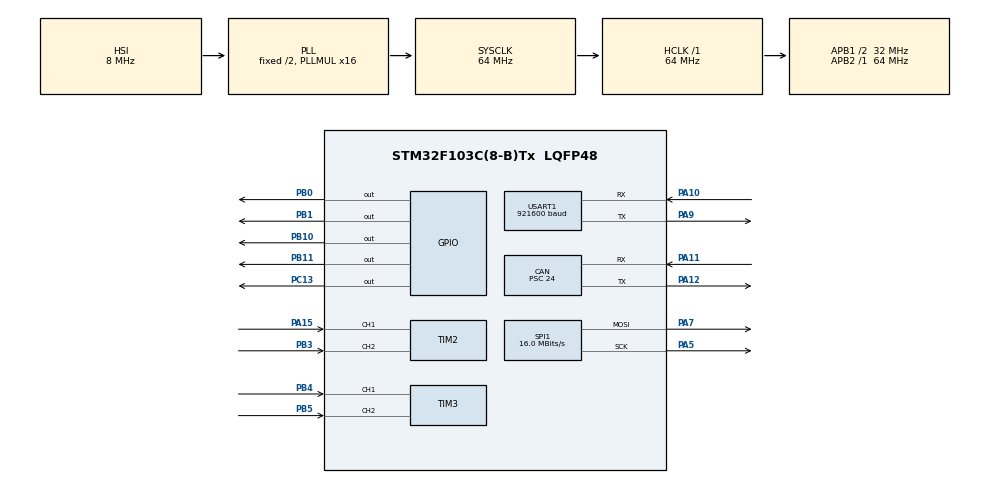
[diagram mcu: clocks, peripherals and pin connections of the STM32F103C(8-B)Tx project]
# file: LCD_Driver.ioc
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CAN.ABOM=ENABLE
CAN.AWUM=ENABLE
CAN.BS1=CAN_BS1_8TQ
CAN.BS2=CAN_BS2_6TQ
CAN.CalculateBaudRate=88888
CAN.CalculateTimeBit=11250
CAN.CalculateTimeQuantum=750.0
CAN.NART=ENABLE
CAN.Prescaler=24
CAN.SJW=CAN_SJW_1TQ
CAN.TXFP=DISABLE
Mcu.Family=STM32F1
Mcu.Name=STM32F103C(8-B)Tx
Mcu.Package=LQFP48
NVIC.CAN1_RX1_IRQn=true\:0\:0\:false\:false\:true\:true\:true\:true
NVIC.PriorityGroup=NVIC_PRIORITYGROUP_4
NVIC.USART1_IRQn=true\:0\:0\:false\:false\:true\:true\:true\:true
NVIC.USB_LP_CAN1_RX0_IRQn=true\:0\:0\:false\:false\:true\:true\:true\:true
PA10.Mode=Asynchronous
PA10.Signal=USART1_RX
PA11.Mode=CAN_Activate
PA11.Signal=CAN_RX
PA12.Mode=CAN_Activate
PA12.Signal=CAN_TX
PA13.Mode=Serial_Wire
PA13.Signal=SYS_JTMS-SWDIO
PA14.Mode=Serial_Wire
PA14.Signal=SYS_JTCK-SWCLK
PA15.Signal=S_TIM2_CH1_ETR
PA5.Mode=TX_Only_Simplex_Unidirect_Master
PA5.Signal=SPI1_SCK
PA7.Mode=TX_Only_Simplex_Unidirect_Master
PA7.Signal=SPI1_MOSI
PA9.Mode=Asynchronous
PA9.Signal=USART1_TX
PB0.Signal=GPIO_Output
PB1.Signal=GPIO_Output
PB10.Signal=GPIO_Output
PB11.Signal=GPIO_Output
PB3.Signal=S_TIM2_CH2
PB4.Signal=S_TIM3_CH1
PB5.Signal=S_TIM3_CH2
PC13-TAMPER-RTC.Signal=GPIO_Output
PD0-OSC_IN.Mode=HSE-External-Oscillator
PD0-OSC_IN.Signal=RCC_OSC_IN
PD1-OSC_OUT.Mode=HSE-External-Oscillator
PD1-OSC_OUT.Signal=RCC_OSC_OUT
ProjectManager.HeapSize=0x200
ProjectManager.StackSize=0x400
ProjectManager.TargetToolchain=MDK-ARM V5.32
RCC.AHBFreq_Value=64000000
RCC.APB1CLKDivider=RCC_HCLK_DIV2
RCC.APB1Freq_Value=32000000
RCC.APB1TimFreq_Value=64000000
RCC.APB2Freq_Value=64000000
RCC.APB2TimFreq_Value=64000000
RCC.HCLKFreq_Value=64000000
RCC.PLLMUL=RCC_PLL_MUL16
RCC.SYSCLKFreq_VALUE=64000000
RCC.SYSCLKSource=RCC_SYSCLKSOURCE_PLLCLK
RCC.USBFreq_Value=64000000
SH.S_TIM2_CH1_ETR.0=TIM2_CH1,Encoder_Interface
SH.S_TIM2_CH2.0=TIM2_CH2,Encoder_Interface
SH.S_TIM3_CH1.0=TIM3_CH1,Encoder_Interface
SH.S_TIM3_CH2.0=TIM3_CH2,Encoder_Interface
SPI1.BaudRatePrescaler=SPI_BAUDRATEPRESCALER_4
SPI1.CalculateBaudRate=16.0 MBits/s
SPI1.Direction=SPI_DIRECTION_2LINES
SPI1.Mode=SPI_MODE_MASTER
SPI1.VirtualType=VM_MASTER
USART1.BaudRate=921600
USART1.VirtualMode=VM_ASYNC
board=custom

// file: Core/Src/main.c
/* USER CODE BEGIN Header */
/**
  ******************************************************************************
  * @file           : main.c
  * @brief          : Main program body
  ******************************************************************************
  * @attention
  *
  * Copyright (c) 2026 STMicroelectronics.
  * All rights reserved.
  *
  * This software is licensed under terms that can be found in the LICENSE file
  * in the root directory of this software component.
  * If no LICENSE file comes with this software, it is provided AS-IS.
  *
  ******************************************************************************
  */
/* USER CODE END Header */
#include "main.h"
#include "can.h"
#include "spi.h"
#include "tim.h"
#include "usart.h"
#include "gpio.h"

/* USER CODE BEGIN Includes */

#include "main.h"
#include "ST7735.h"

#include "test.h"

/* USER CODE END Includes */

void SystemClock_Config(void);

int main(void)
{

  /* MCU Configuration--------------------------------------------------------*/

  /* Reset of all peripherals, Initializes the Flash interface and the Systick. */
  HAL_Init();

  /* Configure the system clock */
  SystemClock_Config();

  /* Initialize all configured peripherals */
  MX_GPIO_Init();
  MX_SPI1_Init();
  MX_USART1_UART_Init();
  MX_TIM2_Init();
  MX_TIM3_Init();
  MX_CAN_Init();
  /* USER CODE BEGIN 2 */

	LCD_Init();
	LCD_Fill(0,0,128,160 ,YELLOW);

Test_Display();

  /* USER CODE END 2 */

  /* Infinite loop */
  while (1)
  {

    /* USER CODE BEGIN 3 */

/*tset
// 测试写入16位数据 0x1234

//	  LCD_Write16(0x1234);
// 期望：先发送 0x12，再发送 0x34
// 原代码：先发送 0x12，然后发送 0x34（但写法容易引起误解）
// 修正后：先发送 0x12，再发送 0x34（写法清晰，类型明确）

uint8_t aaa[100] = {
    1, 2, 3, 4, 5, 6, 7, 8, 9, 10,
    11, 12, 13, 14, 15, 16, 17, 18, 19, 20,
    21, 22, 23, 24, 25, 26, 27, 28, 29, 30,
    31, 32, 33, 34, 35, 36, 37, 38, 39, 40,
    41, 42, 43, 44, 45, 46, 47, 48, 49, 50,
    51, 52, 53, 54, 55, 56, 57, 58, 59, 60,
    61, 62, 63, 64, 65, 66, 67, 68, 69, 70,
    71, 72, 73, 74, 75, 76, 77, 78, 79, 80,
    81, 82, 83, 84, 85, 86, 87, 88, 89, 90,
    91, 92, 93, 94, 95, 96, 97, 98, 99, 100
};
	  LCD_Txn(aaa,100);

	  HAL_Delay(900);
*///test

  }

  /* USER CODE END 3 */
}

void SystemClock_Config(void)
{
  RCC_OscInitTypeDef RCC_OscInitStruct = {0};
  RCC_ClkInitTypeDef RCC_ClkInitStruct = {0};

  /** Initializes the RCC Oscillators according to the specified parameters
  * in the RCC_OscInitTypeDef structure.
  */
  RCC_OscInitStruct.OscillatorType = RCC_OSCILLATORTYPE_HSI;
  RCC_OscInitStruct.HSIState = RCC_HSI_ON;
  RCC_OscInitStruct.HSICalibrationValue = RCC_HSICALIBRATION_DEFAULT;
  RCC_OscInitStruct.PLL.PLLState = RCC_PLL_ON;
  RCC_OscInitStruct.PLL.PLLSource = RCC_PLLSOURCE_HSI_DIV2;
  RCC_OscInitStruct.PLL.PLLMUL = RCC_PLL_MUL16;
  if (HAL_RCC_OscConfig(&RCC_OscInitStruct) != HAL_OK)
  {
    Error_Handler();
  }

  /** Initializes the CPU, AHB and APB buses clocks
  */
  RCC_ClkInitStruct.ClockType = RCC_CLOCKTYPE_HCLK|RCC_CLOCKTYPE_SYSCLK
                              |RCC_CLOCKTYPE_PCLK1|RCC_CLOCKTYPE_PCLK2;
  RCC_ClkInitStruct.SYSCLKSource = RCC_SYSCLKSOURCE_PLLCLK;
  RCC_ClkInitStruct.AHBCLKDivider = RCC_SYSCLK_DIV1;
  RCC_ClkInitStruct.APB1CLKDivider = RCC_HCLK_DIV2;
  RCC_ClkInitStruct.APB2CLKDivider = RCC_HCLK_DIV1;

  if (HAL_RCC_ClockConfig(&RCC_ClkInitStruct, FLASH_LATENCY_2) != HAL_OK)
  {
    Error_Handler();
  }
}

void Error_Handler(void)
{
  __disable_irq();
  while (1)
  {
  }
}
